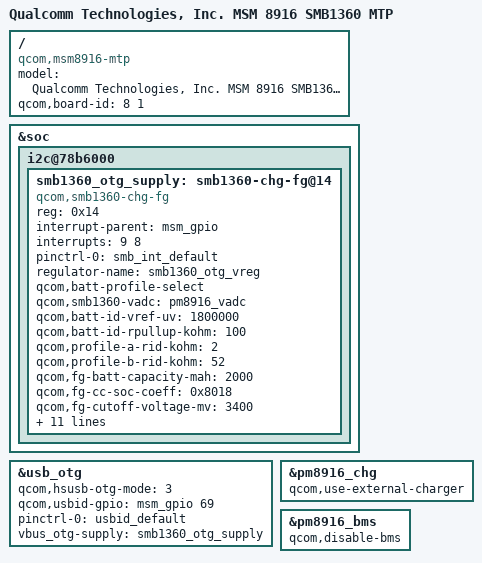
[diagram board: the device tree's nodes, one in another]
/* Copyright (c) 2014, The Linux Foundation. All rights reserved.
*
* This program is free software; you can redistribute it and/or modify
* it under the terms of the GNU General Public License version 2 and
* only version 2 as published by the Free Software Foundation.
*
* This program is distributed in the hope that it will be useful,
* but WITHOUT ANY WARRANTY; without even the implied warranty of
* MERCHANTABILITY or FITNESS FOR A PARTICULAR PURPOSE.  See the
* GNU General Public License for more details.
*/

/dts-v1/;

#include "msm8916-mtp.dtsi"
#include "msm8916-memory.dtsi"

/ {
	model = "Qualcomm Technologies, Inc. MSM 8916 SMB1360 MTP";
	compatible = "qcom,msm8916-mtp", "qcom,msm8916", "qcom,mtp";
	qcom,board-id = <8 1>;
};

&soc {
	//JRD BSP +++ eric.gong@tcl.com "[idol3-4.7][charger] porting smb1360."
	i2c@78b6000 {
		smb1360_otg_supply: smb1360-chg-fg@14 {
			compatible = "qcom,smb1360-chg-fg";
			reg = <0x14>;
			interrupt-parent = <&msm_gpio>;
			interrupts = <9 8>;
			pinctrl-names = "default";
			pinctrl-0 = <&smb_int_default>;
			regulator-name = "smb1360_otg_vreg";
			
			/* battery-profile selection properties */
			qcom,batt-profile-select;
			qcom,smb1360-vadc = <&pm8916_vadc>;
			qcom,batt-id-vref-uv = <1800000>;
			qcom,batt-id-rpullup-kohm = <100>;
			qcom,profile-a-rid-kohm = <2>;
			qcom,profile-b-rid-kohm = <52>;
			
			/* battery capacity */
			qcom,fg-batt-capacity-mah = <2000>;
			qcom,fg-cc-soc-coeff = <0x8018>;
			qcom,fg-cutoff-voltage-mv = <3400>;// add soc 0% voltage 3.4v
			qcom,fg-iterm-ma = <150>;

			/* CC to CV threshold */
			qcom,fg-cc-to-cv-mv = <4330>;
			qcom,thermistor-c1-coeff = <0x86C5>;// B:3435K
			qcom,empty-soc-disabled;
			qcom,chg-inhibit-disabled;
			qcom,float-voltage-mv = <4350>;
			qcom,iterm-ma = <150>;//change from 200ma to 150ma by hw required
			//qcom,charging-disabled;
			qcom,recharge-thresh-mv = <100>;
			qcom,thermal-mitigation = <1000 850 650 0>;
			
			qcom,shdn-after-pwroff;
			qcom,fg-auto-recharge-soc = <98>;//change from 99 to 98 by hw required
		};
	};
	//JRD BSP --- eric.gong@tcl.com "[idol3-4.7][charger] porting smb1360."
};

&usb_otg {
	qcom,hsusb-otg-mode = <3>; // 1 - Peripheral only mode;2 - Host only mode;3 - OTG mode
	qcom,usbid-gpio = <&msm_gpio 69 0>;// change usbid from 37 to 69 for NPI EDL 2015/01/07
	pinctrl-names = "default";
	pinctrl-0 = <&usbid_default>;
	vbus_otg-supply = <&smb1360_otg_supply>;
};

&pm8916_chg {
	status = "ok";
	qcom,use-external-charger;
};

&pm8916_bms {
	status = "ok";
	qcom,disable-bms;
};
